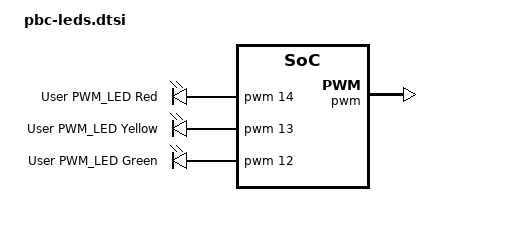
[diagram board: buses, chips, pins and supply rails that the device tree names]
/*
 * Copyright (c) 2024-2025 TiaC Systems
 * SPDX-License-Identifier: Apache-2.0
 */

#include <zephyr/dt-bindings/gpio/gpio.h>
#include <zephyr/dt-bindings/pwm/pwm.h>

/ {
	aliases {
		led0 = &led0;
		led1 = &led1;
		led2 = &led2;
		pwm-led0 = &pwm_led0;
		pwm-led1 = &pwm_led1;
		pwm-led2 = &pwm_led2;
	};

	gpio_leds: gpio_leds {
		compatible = "gpio-leds";
		status = "disabled";

		led0: led_red {
			gpios = <&gpio0 14 GPIO_ACTIVE_HIGH>;
			label = "User LED Red";
		};
		led1: led_yellow {
			gpios = <&gpio0 13 GPIO_ACTIVE_HIGH>;
			label = "User LED Yellow";
		};
		led2: led_green {
			gpios = <&gpio0 12 GPIO_ACTIVE_HIGH>;
			label = "User LED Green";
		};
	};

	pwm_leds: pwm_leds {
		compatible = "pwm-leds";
		status = "okay";

		pwm_led0: pwm_led_red {
			pwms = <&pwm 14 PWM_MSEC(20) PWM_POLARITY_NORMAL>;
			label = "User PWM_LED Red";
		};
		pwm_led1: pwm_led_yellow {
			pwms = <&pwm 13 PWM_MSEC(20) PWM_POLARITY_NORMAL>;
			label = "User PWM_LED Yellow";
		};
		pwm_led2: pwm_led_green {
			pwms = <&pwm 12 PWM_MSEC(20) PWM_POLARITY_NORMAL>;
			label = "User PWM_LED Green";
		};
	};
};

&gpio0 {
	status = "okay";
};

&pwm {
	status = "okay";
	divider-frac-7 = <15>;
	divider-int-7 = <255>;
	divider-frac-6 = <15>;
	divider-int-6 = <255>;
};
